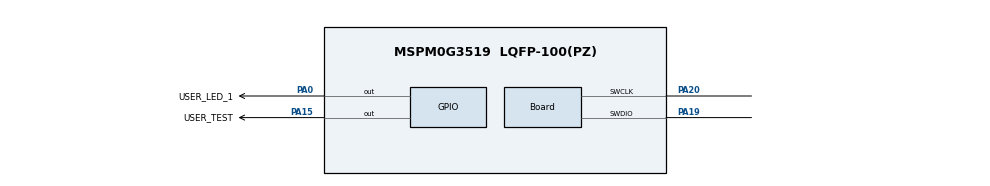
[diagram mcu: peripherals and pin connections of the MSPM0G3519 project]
//@cliArgs --device "MSPM0G351X" --package "LQFP-100(PZ)" --part "Default"
//@v2CliArgs --device "MSPM0G3519" --package "LQFP-100(PZ)"
// @cliArgs --board /ti/boards/LP_MSPM0G3519 --rtos nortos

/**
 * Import the modules used in this configuration.
 */
const GPIO   = scripting.addModule("/ti/driverlib/GPIO", {}, false);
const GPIO1  = GPIO.addInstance();
const SYSCTL = scripting.addModule("/ti/driverlib/SYSCTL");
const TIMER  = scripting.addModule("/ti/driverlib/TIMER", {}, false);
const TIMER1 = TIMER.addInstance();

/**
 * Write custom configuration values to the imported modules.
 */
GPIO1.$name                                 = "GPIO_LEDS";
GPIO1.associatedPins.create(2);
GPIO1.associatedPins[0].$name               = "USER_LED_1";
GPIO1.associatedPins[0].assignedPort        = "PORTA";
GPIO1.associatedPins[0].assignedPin         = "0";
GPIO1.associatedPins[0].initialValue        = "SET";
GPIO1.associatedPins[0].pin.$assign         = "PA0";
GPIO1.associatedPins[1].assignedPort        = "PORTA";
GPIO1.associatedPins[1].assignedPortSegment = "Lower";
GPIO1.associatedPins[1].$name               = "USER_TEST";
GPIO1.associatedPins[1].pin.$assign         = "PA15";

const Board                       = scripting.addModule("/ti/driverlib/Board", {}, false);
Board.peripheral.$assign          = "DEBUGSS";
Board.peripheral.swclkPin.$assign = "PA20";
Board.peripheral.swdioPin.$assign = "PA19";

SYSCTL.forceDefaultClkConfig = true;
SYSCTL.clockTreeEn           = true;

TIMER1.$name              = "TIMER_0";
TIMER1.timerPeriod        = "500 ms";
TIMER1.timerMode          = "PERIODIC";
TIMER1.interrupts         = ["ZERO"];
TIMER1.peripheral.$assign = "TIMG12";

const ProjectConfig              = scripting.addModule("/ti/project_config/ProjectConfig", {}, false);
ProjectConfig.migrationCondition = true;
